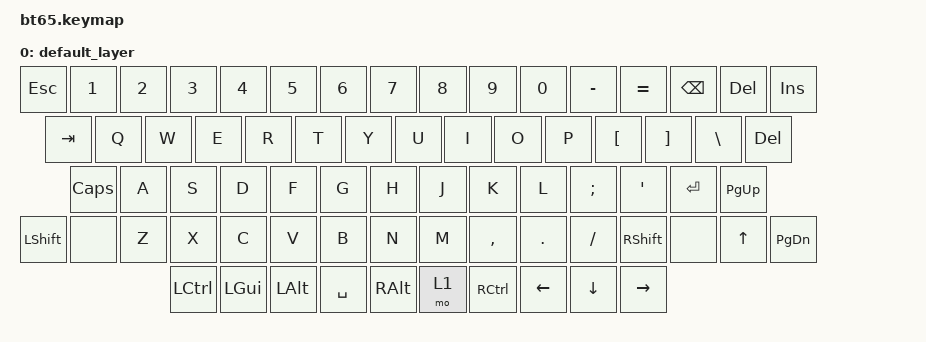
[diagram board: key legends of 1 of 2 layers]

/*
 * Copyright (c) 2020 The ZMK Contributors
 *
 * SPDX-License-Identifier: MIT
 */


/* THIS FILE WAS GENERATED!
 *
 * This file was generated automatically. You may or may not want to
 * edit it directly.
 */

#include <behaviors.dtsi>
#include <dt-bindings/zmk/keys.h>
#include <dt-bindings/zmk/backlight.h>
#include <dt-bindings/zmk/rgb.h>
#include <dt-bindings/zmk/bt.h>

/ {
    keymap {
        compatible = "zmk,keymap";


        default_layer {
            bindings = <
   &kp ESC     &kp N1    &kp N2    &kp N3     &kp N4    &kp N5            &kp N6     &kp N7    &kp N8     &kp N9     &kp N0  &kp MINUS  &kp EQUAL   &kp BSPC  &kp DEL    &kp INS
   &kp TAB      &kp Q     &kp W     &kp E      &kp R     &kp T             &kp Y      &kp U     &kp I      &kp O      &kp P   &kp LBKT   &kp RBKT   &kp BSLH  &kp DEL
  &kp CLCK      &kp A     &kp S     &kp D      &kp F     &kp G             &kp H      &kp J     &kp K      &kp L   &kp SEMI    &kp SQT    &kp RET  &kp PG_UP
 &kp LSHFT      &none     &kp Z     &kp X      &kp C     &kp V             &kp B      &kp N     &kp M  &kp COMMA    &kp DOT   &kp FSLH  &kp RSHFT      &none   &kp UP  &kp PG_DN
            &kp LCTRL  &kp LGUI  &kp LALT  &kp SPACE  &kp RALT             &mo 1  &kp RCTRL  &kp LEFT   &kp DOWN  &kp RIGHT
            >;
        };

        layer_raise {
            bindings = <
  &kp ESC        &kp F1        &kp F2      &kp F3  &kp F4  &kp F5            &kp F6      &kp F7  &kp F8      &kp F9    &kp F10          &kp F11          &kp F12       &bl BL_TOG  &rgb_ug RGB_TOG      &trans
   &trans        &kp UP        &trans      &trans  &trans  &trans            &trans     &kp INS  &trans   &kp PSCRN   &kp SLCK  &kp PAUSE_BREAK           &reset  &rgb_ug RGB_HUI           &trans
 &kp LEFT      &kp DOWN     &kp RIGHT      &trans  &trans  &trans            &trans      &trans  &trans    &kp HOME  &kp PG_UP      &bootloader  &rgb_ug RGB_HUD       &kp C_PREV
   &trans  &kp C_VOL_DN  &kp C_VOL_UP  &kp C_MUTE  &trans  &trans            &trans      &trans  &trans     &kp END  &kp PG_DN       &kp C_NEXT            &none           &trans       &bl BL_INC  &bt BT_PRV
             &bt BT_NXT        &trans      &trans  &trans  &trans            &trans  &bt BT_CLR  &trans  &bl BL_DEC
            >;
        };

    };
};
